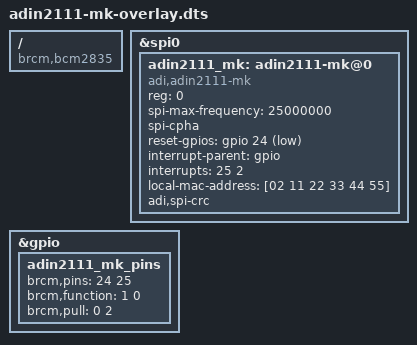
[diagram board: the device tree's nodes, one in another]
/*
 * Device Tree Overlay for ADIN2111-MK Single Interface Ethernet
 * 
 * Author: Murray Kopit <murr2k@gmail.com>
 * 
 * This overlay configures the ADIN2111 chip in single interface mode
 * for direct ethernet operation without switching capabilities.
 */

/dts-v1/;
/plugin/;

/ {
    compatible = "brcm,bcm2835";

    fragment@0 {
        target = <&spi0>;
        __overlay__ {
            #address-cells = <1>;
            #size-cells = <0>;
            status = "okay";

            adin2111_mk: adin2111-mk@0 {
                compatible = "adi,adin2111-mk";
                reg = <0>;  /* Chip select 0 */
                spi-max-frequency = <25000000>;  /* 25 MHz SPI clock */
                
                /* SPI mode and configuration */
                spi-cpha;  /* Clock phase */
                
                /* Reset GPIO (optional) */
                reset-gpios = <&gpio 24 1>;  /* GPIO 24, active high */
                
                /* Interrupt pin */
                interrupt-parent = <&gpio>;
                interrupts = <25 2>;  /* GPIO 25, falling edge */
                
                /* MAC address (optional, will use random if not specified) */
                local-mac-address = [02 11 22 33 44 55];
                
                /* Enable SPI CRC if hardware supports it */
                adi,spi-crc;
                
                /* Additional properties for single interface mode */
                status = "okay";
            };
        };
    };

    fragment@1 {
        target = <&gpio>;
        __overlay__ {
            adin2111_mk_pins: adin2111_mk_pins {
                brcm,pins = <24 25>;  /* Reset and interrupt pins */
                brcm,function = <1 0>; /* Output, Input */
                brcm,pull = <0 2>;     /* No pull, Pull-up */
            };
        };
    };
};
